# MK40D7 register map
File version: 1.6
Registers are 32-bit, read-write, reset 0x0 unless marked. A register's access mark holds for its fields unless they carry their own. Offsets are from the block's base; [hi:lo] are bit positions; {n}, {i} and the like mark numbered series; 'fields as' and 'values as' point back to an identical list.

## OSC — Oscillator
Base 0x40065000; register names take the prefix OSC_
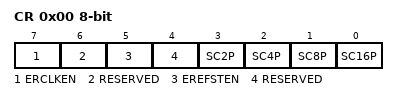
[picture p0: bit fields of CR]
0x00 CR 8-bit access per field — OSC Control Register
  [7] ERCLKEN rw — External Reference Enable
    0=External reference clock is inactive; 1=External reference clock is enabled
  [6] RESERVED ro
  [5] EREFSTEN rw — External Reference Stop Enable
    0=External reference clock is disabled in Stop mode; 1=External reference clock stays enabled in Stop mode if ERCLKEN is set before entering Stop mode
  [4] RESERVED ro
  [3] SC2P rw — Oscillator 2 pF Capacitor Load Configure
    0=Disable the selection; 1=Add 2 pF capacitor to the oscillator load
  [2] SC4P rw — Oscillator 4 pF Capacitor Load Configure
    0=Disable the selection; 1=Add 4 pF capacitor to the oscillator load
  [1] SC8P rw — Oscillator 8 pF Capacitor Load Configure
    0=Disable the selection; 1=Add 8 pF capacitor to the oscillator load
  [0] SC16P rw — Oscillator 16 pF Capacitor Load Configure
    0=Disable the selection; 1=Add 16 pF capacitor to the oscillator load

## VREF — Voltage Reference
Base 0x40074000; register names take the prefix VREF_
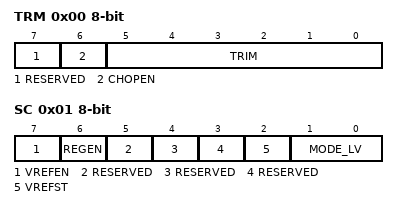
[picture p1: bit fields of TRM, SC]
0x00 TRM 8-bit access per field — VREF Trim Register
  [7] RESERVED ro
  [6] CHOPEN rw — Chop oscillator enable. When set, internal chopping operation is enabled and the internal analog offset will be minimized.
    0=Chop oscillator is disabled; 1=Chop oscillator is enabled
  [5:0] TRIM rw — Trim bits
    0=Min; 63=Max
0x01 SC 8-bit access per field — VREF Status and Control Register
  [7] VREFEN rw — Internal Voltage Reference enable
    0=The module is disabled; 1=The module is enabled
  [6] REGEN rw — Regulator enable
    0=Internal 1.75 V regulator is disabled; 1=Internal 1.75 V regulator is enabled
  [5] RESERVED ro
  [4] RESERVED ro
  [3] RESERVED ro
  [2] VREFST ro — Internal Voltage Reference stable
    0=The module is disabled or not stable; 1=The module is stable
  [1:0] MODE_LV rw — Buffer Mode selection
    0=Bandgap on only, for stabilization and startup; 1=Low-power buffer mode enabled; 2=Tight-regulation buffer enabled

## LLWU — Low leakage wakeup unit
Base 0x4007C000; register names take the prefix LLWU_
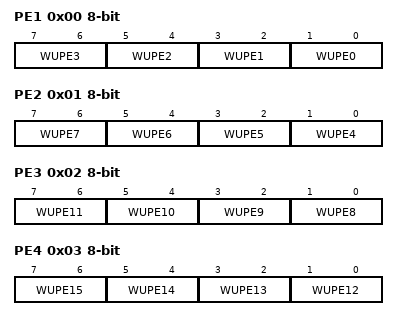
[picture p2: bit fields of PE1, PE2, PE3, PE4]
0x00 PE1 8-bit — LLWU Pin Enable 1 Register
  [all] fields
    0=External input pin disabled as wakeup input; 1=External input pin enabled with rising edge detection; 2=External input pin enabled with falling edge detection; 3=External input pin enabled with any change detection
  [2n+1:2n] WUPE{n} (n=0..3) — Wakeup Pin Enable for LLWU_P{n}
0x01 PE2 8-bit — LLWU Pin Enable 2 Register
  [all] fields
    values as the fields of PE1
  [2n-7:2n-8] WUPE{n} (n=4..7) — Wakeup Pin Enable for LLWU_P{n}
0x02 PE3 8-bit — LLWU Pin Enable 3 Register
  [all] fields
    values as the fields of PE1
  [2n-15:2n-16] WUPE{n} (n=8..11) — Wakeup Pin Enable for LLWU_P{n}
0x03 PE4 8-bit — LLWU Pin Enable 4 Register
  [all] fields
    values as the fields of PE1
  [2n-23:2n-24] WUPE{n} (n=12..15) — Wakeup Pin Enable for LLWU_P{n}
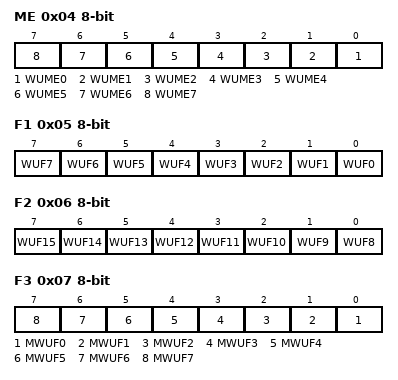
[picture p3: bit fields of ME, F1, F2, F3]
0x04 ME 8-bit — LLWU Module Enable Register
  [all] fields
    0=Internal module flag not used as wakeup source; 1=Internal module flag used as wakeup source
  [n] WUME{n} (n=0..7) — Wakeup Module Enable for Module {n}
0x05 F1 8-bit — LLWU Flag 1 Register
  [n] WUF{n} (n=0..7) — Wakeup Flag for LLWU_P{n}
    0=LLWU_P{n} input was not a wakeup source; 1=LLWU_P{n} input was a wakeup source
0x06 F2 8-bit — LLWU Flag 2 Register
  [n-8] WUF{n} (n=8..15) — Wakeup Flag for LLWU_P{n}
    values as F1.WUF0
0x07 F3 8-bit ro — LLWU Flag 3 Register
  [n] MWUF{n} (n=0..7) — Wakeup flag for module {n}
    0=Module {n} input was not a wakeup source; 1=Module {n} input was a wakeup source
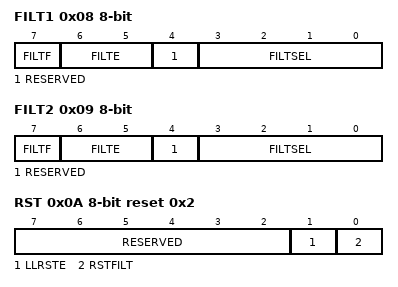
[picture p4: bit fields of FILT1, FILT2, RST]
0x08 FILT1 8-bit access per field — LLWU Pin Filter 1 Register
  [7] FILTF rw — Filter Detect Flag
    0=Pin Filter 1 was not a wakeup source; 1=Pin Filter 1 was a wakeup source
  [6:5] FILTE rw — Digital Filter on External Pin
    0=Filter disabled; 1=Filter posedge detect enabled; 2=Filter negedge detect enabled; 3=Filter any edge detect enabled
  [4] RESERVED ro
  [3:0] FILTSEL rw — Filter pin select
    0=Select LLWU_P0 for filter; 15=Select LLWU_P15 for filter
0x09 FILT2 8-bit access per field — LLWU Pin Filter 2 Register
  [7] FILTF rw — Filter Detect Flag
    0=Pin Filter 2 was not a wakeup source; 1=Pin Filter 2 was a wakeup source
  [6:5] FILTE rw — Digital Filter on External Pin
    values as FILT1.FILTE
  [4] RESERVED ro
  [3:0] FILTSEL rw — Filter pin select
    0=Select LLWU_P0 for filter; 15=Select LLWU_P15 for filter
0x0A RST 8-bit access per field reset 0x2 — LLWU Reset Enable Register
  [7:2] RESERVED ro
  [1] LLRSTE rw — Low Leakage mode RESET enable
    0=RESET pin not enabled as a leakage mode exit source; 1=RESET pin enabled as a low leakage mode exit source
  [0] RSTFILT rw — Digital Filter on RESET Pin
    0=Filter not enabled; 1=Filter enabled
